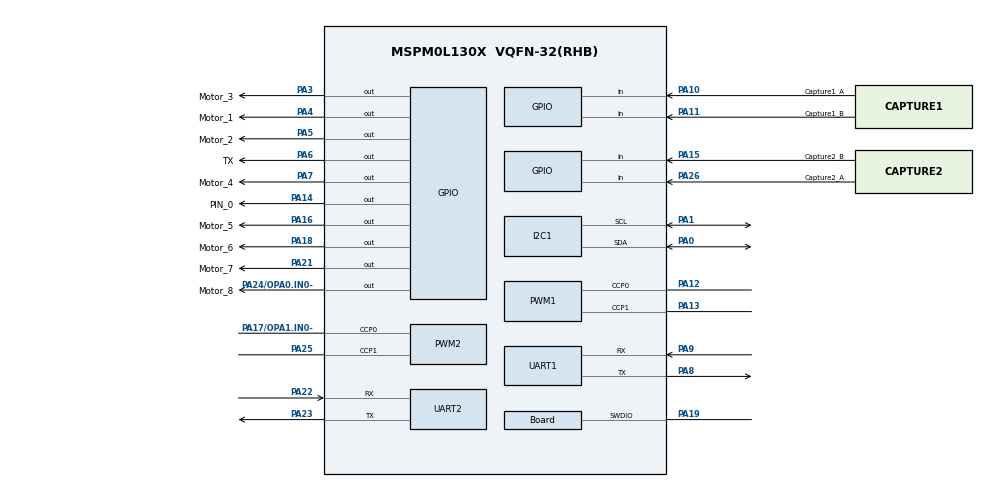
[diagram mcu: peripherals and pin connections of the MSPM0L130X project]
/**
 * @cliArgs --device "MSPM0L130X" --package "VQFN-32(RHB)" --part "Default" --product "mspm0_sdk@2.01.00.03"
 * @versions {"tool":"1.19.0+3426"}
 */

/**
 * Import the modules used in this configuration.
 */
const Board  = scripting.addModule("/ti/driverlib/Board");
const GPIO   = scripting.addModule("/ti/driverlib/GPIO", {}, false);
const GPIO1  = GPIO.addInstance();
const GPIO2  = GPIO.addInstance();
const GPIO3  = GPIO.addInstance();
const GPIO4  = GPIO.addInstance();
const I2C    = scripting.addModule("/ti/driverlib/I2C", {}, false);
const I2C1   = I2C.addInstance();
const PWM    = scripting.addModule("/ti/driverlib/PWM", {}, false);
const PWM1   = PWM.addInstance();
const PWM2   = PWM.addInstance();
const SYSCTL = scripting.addModule("/ti/driverlib/SYSCTL");
const TIMER  = scripting.addModule("/ti/driverlib/TIMER", {}, false);
const TIMER1 = TIMER.addInstance();
const UART   = scripting.addModule("/ti/driverlib/UART", {}, false);
const UART1  = UART.addInstance();
const UART2  = UART.addInstance();

/**
 * Write custom configuration values to the imported modules.
 */
Board.peripheral.swdioPin.$assign = "PA19";

GPIO1.port                               = "PORTA";
GPIO1.$name                              = "HCSR04";
GPIO1.associatedPins.create(2);
GPIO1.associatedPins[0].subOutputPolicy  = "TOGGLE";
GPIO1.associatedPins[0].$name            = "TX";
GPIO1.associatedPins[0].pin.$assign      = "PA6";
GPIO1.associatedPins[1].initialValue     = "SET";
GPIO1.associatedPins[1].$name            = "RX";
GPIO1.associatedPins[1].direction        = "INPUT";
GPIO1.associatedPins[1].internalResistor = "PULL_UP";
GPIO1.associatedPins[1].ioStructure      = "SD";

GPIO2.$name                          = "Motor";
GPIO2.associatedPins.create(8);
GPIO2.associatedPins[0].$name        = "Motor_1";
GPIO2.associatedPins[0].initialValue = "SET";
GPIO2.associatedPins[0].pin.$assign  = "PA4";
GPIO2.associatedPins[1].$name        = "Motor_2";
GPIO2.associatedPins[1].pin.$assign  = "PA5";
GPIO2.associatedPins[2].$name        = "Motor_3";
GPIO2.associatedPins[2].initialValue = "SET";
GPIO2.associatedPins[2].pin.$assign  = "PA3";
GPIO2.associatedPins[3].$name        = "Motor_4";
GPIO2.associatedPins[3].pin.$assign  = "PA7";
GPIO2.associatedPins[4].initialValue = "SET";
GPIO2.associatedPins[4].$name        = "Motor_5";
GPIO2.associatedPins[4].pin.$assign  = "PA16";
GPIO2.associatedPins[5].$name        = "Motor_6";
GPIO2.associatedPins[5].pin.$assign  = "PA18";
GPIO2.associatedPins[6].initialValue = "SET";
GPIO2.associatedPins[6].$name        = "Motor_7";
GPIO2.associatedPins[6].pin.$assign  = "PA21";
GPIO2.associatedPins[7].$name        = "Motor_8";
GPIO2.associatedPins[7].pin.$assign  = "PA24/OPA0.IN0-";

GPIO3.$name                         = "Tracking";
GPIO3.associatedPins[0].$name       = "PIN_0";
GPIO3.associatedPins[0].pin.$assign = "PA14";

GPIO4.$name                         = "Encoder_Capture";
GPIO4.associatedPins.create(4);
GPIO4.associatedPins[0].$name       = "Capture1_A";
GPIO4.associatedPins[0].direction   = "INPUT";
GPIO4.associatedPins[0].interruptEn = true;
GPIO4.associatedPins[0].polarity    = "RISE";
GPIO4.associatedPins[0].pin.$assign = "PA10";
GPIO4.associatedPins[1].$name       = "Capture1_B";
GPIO4.associatedPins[1].direction   = "INPUT";
GPIO4.associatedPins[1].interruptEn = true;
GPIO4.associatedPins[1].polarity    = "RISE";
GPIO4.associatedPins[1].pin.$assign = "PA11";
GPIO4.associatedPins[2].$name       = "Capture2_A";
GPIO4.associatedPins[2].direction   = "INPUT";
GPIO4.associatedPins[2].polarity    = "RISE";
GPIO4.associatedPins[2].interruptEn = true;
GPIO4.associatedPins[2].pin.$assign = "PA26";
GPIO4.associatedPins[3].$name       = "Capture2_B";
GPIO4.associatedPins[3].direction   = "INPUT";
GPIO4.associatedPins[3].polarity    = "RISE";
GPIO4.associatedPins[3].interruptEn = true;
GPIO4.associatedPins[3].pin.$assign = "PA15";

I2C1.$name                           = "I2C_0";
I2C1.basicEnableController           = true;
I2C1.basicControllerStandardBusSpeed = "Fast";
I2C1.peripheral.sdaPin.$assign       = "PA0";
I2C1.peripheral.sclPin.$assign       = "PA1";
I2C1.sdaPinConfig.$name              = "ti_driverlib_gpio_GPIOPinGeneric2";
I2C1.sclPinConfig.$name              = "ti_driverlib_gpio_GPIOPinGeneric3";

PWM1.$name                              = "PWM_12";
PWM1.interrupts                         = ["ZERO_EVENT"];
PWM1.timerCount                         = 100;
PWM1.clockPrescale                      = 32;
PWM1.peripheral.$assign                 = "TIMG0";
PWM1.peripheral.ccp0Pin.$assign         = "PA12";
PWM1.peripheral.ccp1Pin.$assign         = "PA13";
PWM1.PWM_CHANNEL_0.$name                = "ti_driverlib_pwm_PWMTimerCC2";
PWM1.PWM_CHANNEL_0.dutyCycle            = 1;
PWM1.PWM_CHANNEL_1.$name                = "ti_driverlib_pwm_PWMTimerCC3";
PWM1.PWM_CHANNEL_1.dutyCycle            = 1;
PWM1.ccp0PinConfig.direction            = scripting.forceWrite("OUTPUT");
PWM1.ccp0PinConfig.hideOutputInversion  = scripting.forceWrite(false);
PWM1.ccp0PinConfig.onlyInternalResistor = scripting.forceWrite(false);
PWM1.ccp0PinConfig.passedPeripheralType = scripting.forceWrite("Digital");
PWM1.ccp0PinConfig.$name                = "ti_driverlib_gpio_GPIOPinGeneric7";
PWM1.ccp1PinConfig.direction            = scripting.forceWrite("OUTPUT");
PWM1.ccp1PinConfig.hideOutputInversion  = scripting.forceWrite(false);
PWM1.ccp1PinConfig.onlyInternalResistor = scripting.forceWrite(false);
PWM1.ccp1PinConfig.passedPeripheralType = scripting.forceWrite("Digital");
PWM1.ccp1PinConfig.$name                = "ti_driverlib_gpio_GPIOPinGeneric8";

PWM2.$name                              = "PWM_34";
PWM2.clockPrescale                      = 32;
PWM2.timerCount                         = 100;
PWM2.peripheral.ccp0Pin.$assign         = "PA17/OPA1.IN0-";
PWM2.peripheral.ccp1Pin.$assign         = "PA25";
PWM2.PWM_CHANNEL_0.$name                = "ti_driverlib_pwm_PWMTimerCC0";
PWM2.PWM_CHANNEL_0.dutyCycle            = 1;
PWM2.PWM_CHANNEL_1.$name                = "ti_driverlib_pwm_PWMTimerCC1";
PWM2.PWM_CHANNEL_1.dutyCycle            = 1;
PWM2.ccp0PinConfig.direction            = scripting.forceWrite("OUTPUT");
PWM2.ccp0PinConfig.hideOutputInversion  = scripting.forceWrite(false);
PWM2.ccp0PinConfig.onlyInternalResistor = scripting.forceWrite(false);
PWM2.ccp0PinConfig.passedPeripheralType = scripting.forceWrite("Digital");
PWM2.ccp0PinConfig.$name                = "ti_driverlib_gpio_GPIOPinGeneric6";
PWM2.ccp1PinConfig.direction            = scripting.forceWrite("OUTPUT");
PWM2.ccp1PinConfig.hideOutputInversion  = scripting.forceWrite(false);
PWM2.ccp1PinConfig.onlyInternalResistor = scripting.forceWrite(false);
PWM2.ccp1PinConfig.passedPeripheralType = scripting.forceWrite("Digital");
PWM2.ccp1PinConfig.$name                = "ti_driverlib_gpio_GPIOPinGeneric9";

SYSCTL.clockTreeEn = true;

TIMER1.$name            = "TIMER_0";
TIMER1.timerClkDiv      = 8;
TIMER1.timerClkPrescale = 64;
TIMER1.interrupts       = ["ZERO"];
TIMER1.timerMode        = "PERIODIC";
TIMER1.timerPeriod      = "30 ms";

UART1.$name                    = "UART_0";
UART1.enabledInterrupts        = ["RX","TX"];
UART1.peripheral.rxPin.$assign = "PA9";
UART1.peripheral.txPin.$assign = "PA8";
UART1.txPinConfig.$name        = "ti_driverlib_gpio_GPIOPinGeneric0";
UART1.rxPinConfig.$name        = "ti_driverlib_gpio_GPIOPinGeneric1";

UART2.$name                    = "UART_1";
UART2.enabledInterrupts        = ["RX","TX"];
UART2.peripheral.rxPin.$assign = "PA22";
UART2.peripheral.txPin.$assign = "PA23";
UART2.txPinConfig.$name        = "ti_driverlib_gpio_GPIOPinGeneric4";
UART2.rxPinConfig.$name        = "ti_driverlib_gpio_GPIOPinGeneric5";

/**
 * Pinmux solution for unlocked pins/peripherals. This ensures that minor changes to the automatic solver in a future
 * version of the tool will not impact the pinmux you originally saw.  These lines can be completely deleted in order to
 * re-solve from scratch.
 */
Board.peripheral.$suggestSolution            = "DEBUGSS";
Board.peripheral.swclkPin.$suggestSolution   = "PA20";
GPIO1.associatedPins[1].pin.$suggestSolution = "PA2";
I2C1.peripheral.$suggestSolution             = "I2C0";
PWM2.peripheral.$suggestSolution             = "TIMG4";
TIMER1.peripheral.$suggestSolution           = "TIMG1";
UART1.peripheral.$suggestSolution            = "UART0";
UART2.peripheral.$suggestSolution            = "UART1";
